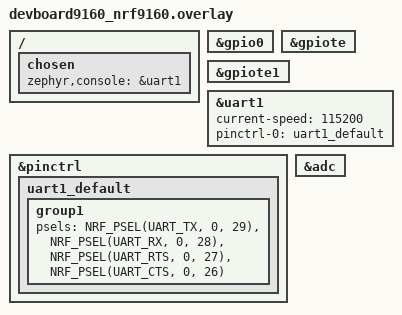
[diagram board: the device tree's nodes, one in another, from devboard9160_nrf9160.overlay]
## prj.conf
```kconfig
CONFIG_GPIO=y

CONFIG_CONSOLE=y
CONFIG_SERIAL=y
CONFIG_UART_CONSOLE=y

CONFIG_LOG=y
CONFIG_LOG_INFO_COLOR_GREEN=y
CONFIG_LOG_DBG_COLOR_BLUE=y

#####NRF ADC drivers
CONFIG_NRFX_SAADC=y
CONFIG_NRFX_PPI=y
CONFIG_NRFX_DPPI=y

CONFIG_NRFX_TIMER2=y
```

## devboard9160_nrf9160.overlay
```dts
// To get started, press Ctrl+Space to bring up the completion menu and view the available nodes.

// You can also use the buttons in the sidebar to perform actions on nodes.
// Actions currently available include:

// * Enabling / disabling the node
// * Adding the bus to a bus
// * Removing the node
// * Connecting ADC channels

// For more help, browse the DeviceTree documentation at https://docs.zephyrproject.org/latest/guides/dts/index.html
// You can also visit the nRF DeviceTree extension documentation at https://docs.nordicsemi.com/bundle/nrf-connect-vscode/page/guides/ncs_configure_app.html#devicetree-support-in-the-extension


&gpio0 {
	status = "okay";
};

&gpiote {
	status = "okay";
};

&gpiote1 {
	status = "okay";
};

&uart1 {
	status = "okay";
	current-speed = <115200>;
	pinctrl-0 = <&uart1_default>;
	pinctrl-names = "default";
};

&pinctrl {
	uart1_default: uart1_default {
		group1 {
			psels = <NRF_PSEL(UART_TX, 0, 29)>,
					<NRF_PSEL(UART_RX, 0, 28)>,
					<NRF_PSEL(UART_RTS, 0, 27)>,
					<NRF_PSEL(UART_CTS, 0, 26)>;
		};
	};
};

/ {
	chosen {
		zephyr,console = &uart1;
	};
};

&adc {
	status = "okay";
};
```

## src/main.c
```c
/*
 * Copyright (c) 2023 Nordic Semiconductor ASA
 *
 * SPDX-License-Identifier: LicenseRef-Nordic-5-Clause
 */

#include <zephyr/kernel.h>
#include <zephyr/logging/log.h>
#include <nrfx_saadc.h>
#include <nrfx_timer.h>
#include <helpers/nrfx_gppi.h>
#include <nrfx_dppi.h>

LOG_MODULE_REGISTER(main, LOG_LEVEL_DBG);

/* STEP 3.1 - Define the SAADC sample interval in microseconds */
#define SAADC_SAMPLE_INTERVAL_US 50

/* STEP 4.1 - Define the buffer size for the SAADC */
#define SAADC_BUFFER_SIZE 8000

/* STEP 4.6 - Declare the struct to hold the configuration for the SAADC channel used to sample the battery voltage */
#define SAADC_INPUT_PIN NRF_SAADC_INPUT_AIN0
static nrfx_saadc_channel_t channel = NRFX_SAADC_DEFAULT_CHANNEL_SE(SAADC_INPUT_PIN, 0);

/* STEP 3.2 - Declaring an instance of nrfx_timer for TIMER2. */
#define TIMER_INSTANCE_NUMBER 2
const nrfx_timer_t timer_instance = NRFX_TIMER_INSTANCE(TIMER_INSTANCE_NUMBER);

/* STEP 4.2 - Declare the buffers for the SAADC */
static int16_t saadc_sample_buffer[2][SAADC_BUFFER_SIZE];

/* STEP 4.3 - Declare variable used to keep track of which buffer was last assigned to the SAADC driver */
static uint32_t saadc_current_buffer = 0;

static void configure_timer(void)
{
    nrfx_err_t err;

    /* STEP 3.3 - Declaring timer config and intialize nrfx_timer instance. */
    nrfx_timer_config_t timer_config = NRFX_TIMER_DEFAULT_CONFIG(1000000);
    err = nrfx_timer_init(&timer_instance, &timer_config, NULL);
    if (err != NRFX_SUCCESS)
    {
        LOG_ERR("nrfx_timer_init error: %08x", err);
        return;
    }

    /* STEP 3.4 - Set compare channel 0 to generate event every SAADC_SAMPLE_INTERVAL_US. */

    uint32_t timer_ticks = nrfx_timer_us_to_ticks(&timer_instance, SAADC_SAMPLE_INTERVAL_US);
    nrfx_timer_extended_compare(&timer_instance, NRF_TIMER_CC_CHANNEL0, timer_ticks, NRF_TIMER_SHORT_COMPARE0_CLEAR_MASK, false);
}

static void saadc_event_handler(nrfx_saadc_evt_t const *p_event)
{
    nrfx_err_t err;
    switch (p_event->type)
    {
    case NRFX_SAADC_EVT_READY:

        /* STEP 5.1 - Buffer is ready, timer (and sampling) can be started. */
        nrfx_timer_enable(&timer_instance);

        break;

    case NRFX_SAADC_EVT_BUF_REQ:

        /* STEP 5.2 - Set up the next available buffer. Alternate between buffer 0 and 1 */
        err = nrfx_saadc_buffer_set(saadc_sample_buffer[(saadc_current_buffer++) % 2], SAADC_BUFFER_SIZE);
        if (err != NRFX_SUCCESS)
        {
            LOG_ERR("nrfx_saadc_buffer_set error: %08x", err);
            return;
        }

        break;

    case NRFX_SAADC_EVT_DONE:

        /* STEP 5.3 - Buffer has been filled. Do something with the data and proceed */
        int64_t average = 0;
        int16_t max = INT16_MIN;
        int16_t min = INT16_MAX;
        int16_t current_value;
        for (int i = 0; i < p_event->data.done.size; i++)
        {
            current_value = ((int16_t *)(p_event->data.done.p_buffer))[i];
            average += current_value;
            if (current_value > max)
            {
                max = current_value;
            }
            if (current_value < min)
            {
                min = current_value;
            }
        }
        average = average / p_event->data.done.size;
        LOG_INF("SAADC buffer at 0x%x filled with %d samples", (uint32_t)p_event->data.done.p_buffer,
                p_event->data.done.size);
        LOG_INF("AVG=%d, MIN=%d, MAX=%d", (int16_t)average, min, max);

        break;

    default:
        LOG_INF("Unhandled SAADC evt %d", p_event->type);
        break;
    }
}

static void configure_saadc(void)
{
    nrfx_err_t err;

    /* STEP 4.4 - Connect ADC interrupt to nrfx interrupt handler */
    IRQ_CONNECT(DT_IRQN(DT_NODELABEL(adc)),
                DT_IRQ(DT_NODELABEL(adc), priority),
                nrfx_isr, nrfx_saadc_irq_handler, 0);

    /* STEP 4.5 - Initialize the nrfx_SAADC driver */
    err = nrfx_saadc_init(DT_IRQ(DT_NODELABEL(adc), priority));
    if (err != NRFX_SUCCESS)
    {
        LOG_ERR("nrfx_saadc_init error: %08x", err);
        return;
    }

    /* STEP 4.7 - Change gain config in default config and apply channel configuration */
    channel.channel_config.gain = NRF_SAADC_GAIN1_6;
    err = nrfx_saadc_channels_config(&channel, 1);
    if (err != NRFX_SUCCESS)
    {
        LOG_ERR("nrfx_saadc_channels_config error: %08x", err);
        return;
    }

    /* STEP 4.8 - Configure channel 0 in advanced mode with event handler (non-blocking mode) */
    nrfx_saadc_adv_config_t saadc_adv_config = NRFX_SAADC_DEFAULT_ADV_CONFIG;
    err = nrfx_saadc_advanced_mode_set(BIT(0),
                                       NRF_SAADC_RESOLUTION_12BIT,
                                       &saadc_adv_config,
                                       saadc_event_handler);
    if (err != NRFX_SUCCESS)
    {
        LOG_ERR("nrfx_saadc_advanced_mode_set error: %08x", err);
        return;
    }

    /* STEP 4.9 - Configure two buffers to make use of double-buffering feature of SAADC */
    err = nrfx_saadc_buffer_set(saadc_sample_buffer[0], SAADC_BUFFER_SIZE);
    if (err != NRFX_SUCCESS)
    {
        LOG_ERR("nrfx_saadc_buffer_set error: %08x", err);
        return;
    }
    err = nrfx_saadc_buffer_set(saadc_sample_buffer[1], SAADC_BUFFER_SIZE);
    if (err != NRFX_SUCCESS)
    {
        LOG_ERR("nrfx_saadc_buffer_set error: %08x", err);
        return;
    }

    /* STEP 4.10 - Trigger the SAADC. This will not start sampling, but will prepare buffer for sampling triggered through PPI */
    err = nrfx_saadc_mode_trigger();
    if (err != NRFX_SUCCESS)
    {
        LOG_ERR("nrfx_saadc_mode_trigger error: %08x", err);
        return;
    }
}

static void configure_ppi(void)
{
    nrfx_err_t err;
    /* STEP 6.1 - Declare variables used to hold the (D)PPI channel number */
    uint8_t m_saadc_sample_ppi_channel;
    uint8_t m_saadc_start_ppi_channel;

    /* STEP 6.2 - Trigger task sample from timer */
    err = nrfx_gppi_channel_alloc(&m_saadc_sample_ppi_channel);
    if (err != NRFX_SUCCESS)
    {
        LOG_ERR("nrfx_gppi_channel_alloc error: %08x", err);
        return;
    }

    err = nrfx_gppi_channel_alloc(&m_saadc_start_ppi_channel);
    if (err != NRFX_SUCCESS)
    {
        LOG_ERR("nrfx_gppi_channel_alloc error: %08x", err);
        return;
    }

    /* STEP 6.3 - Trigger task sample from timer */
    nrfx_gppi_channel_endpoints_setup(m_saadc_sample_ppi_channel,
                                      nrfx_timer_compare_event_address_get(&timer_instance,
                                                                           NRF_TIMER_CC_CHANNEL0),
                                      nrf_saadc_task_address_get(NRF_SAADC, NRF_SAADC_TASK_SAMPLE));

    /* STEP 6.4 - Trigger task start from end event */
    nrfx_gppi_channel_endpoints_setup(m_saadc_start_ppi_channel,
                                      nrf_saadc_event_address_get(NRF_SAADC, NRF_SAADC_EVENT_END),
                                      nrf_saadc_task_address_get(NRF_SAADC, NRF_SAADC_TASK_START));

    /* STEP 6.5 - Enable both (D)PPI channels */
    nrfx_gppi_channels_enable(BIT(m_saadc_sample_ppi_channel));
    nrfx_gppi_channels_enable(BIT(m_saadc_start_ppi_channel));
}

int main(void)
{
    configure_timer();
    configure_saadc();
    configure_ppi();
    k_sleep(K_FOREVER);
}
```
